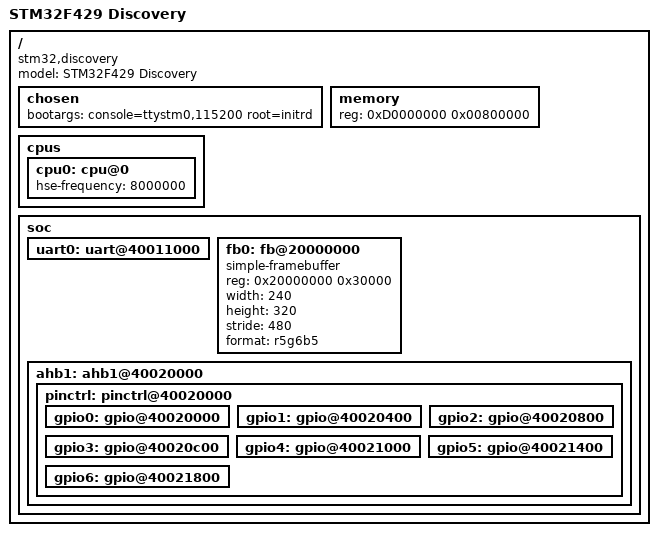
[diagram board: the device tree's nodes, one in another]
/dts-v1/;
#include "stm32f4.dtsi"

/ {
	model = "STM32F429 Discovery";
	compatible = "stm32,discovery";

	chosen {
		bootargs = "console=ttystm0,115200 root=initrd";
	};

	memory {
		reg = <0xD0000000 0x00800000>;
	};
	
	cpus {
		cpu0: cpu@0{
			hse-frequency = <8000000>;
		};
	};
	
	soc {
		uart0: uart@40011000 {
			status = "ok";
		};

		fb0: fb@20000000  {
			reg = <0x20000000 0x30000>;
			compatible = "simple-framebuffer";
			width = <240>;
			height = <320>;
			stride = <480>;
			format = "r5g6b5";
		};
		
		ahb1: ahb1@40020000 {
			pinctrl: pinctrl@40020000 {
				gpio0: gpio@40020000{
					status = "ok";
				};
				
				gpio1: gpio@40020400{
					status = "ok";
				};
				gpio2: gpio@40020800{
					status = "ok";
				};
				gpio3: gpio@40020c00{
					status = "ok";
				};
				gpio4: gpio@40021000{
					status = "ok";
				};
				gpio5: gpio@40021400{
					status = "ok";
				};
				gpio6: gpio@40021800{
					status = "ok";
				};
				
			};
		};
	};
};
